# R7FA0L107 register map
Vendor: Renesas Electronics Corporation; Series: RA0; File version: 1.10.01
CPU: CM23 r1p0, little endian, no MPU, no FPU, VTOR, 2 interrupt priority bits, 64 interrupts
Registers are 16-bit, read-write, reset 0x0 unless marked. A register's access mark holds for its fields unless they carry their own. Offsets are from the block's base; [hi:lo] are bit positions; {n}, {i} and the like mark numbered series; 'fields as' and 'values as' point back to an identical list.

## IWDT — Independent Watchdog Timer
Base 0x40044400
0x00 IWDTRR 8-bit reset 0xFF — IWDT Refresh Register
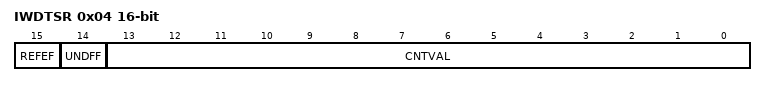
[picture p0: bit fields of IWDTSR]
0x04 IWDTSR — IWDT Status Register
  [15] REFEF — Refresh Error Flag
    0=No refresh error occurred; 1=Refresh error occurred
  [14] UNDFF — Underflow Flag
    0=No underflow occurred; 1=Underflow occurred
  [13:0] CNTVAL ro — Down-counter Value

## MSTP — Module Stop Control
Base 0x40047000
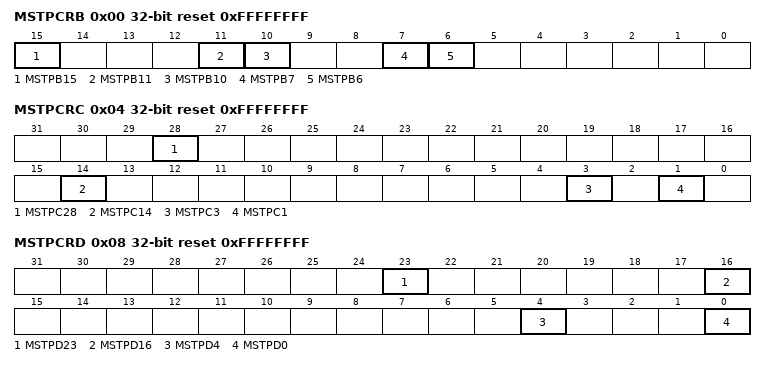
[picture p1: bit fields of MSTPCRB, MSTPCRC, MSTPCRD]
0x00 MSTPCRB 32-bit reset 0xFFFFFFFF — Module Stop Control Register B
  [all] fields
    0=Cancel the module-stop state; 1=Enter the module-stop state
  [15] MSTPB15 — Serial Interface UARTA Module Stop
  [11] MSTPB11 — I2C Bus Interface Module Stop
  [10] MSTPB10 — I2C Bus Interface Module Stop
  [7] MSTPB7 — Serial Array Unit 1 Module Stop
  [6] MSTPB6 — Serial Array Unit 0 Module Stop
0x04 MSTPCRC 32-bit reset 0xFFFFFFFF — Module Stop Control Register C
  [all] fields
    values as the fields of MSTPCRB
  [28] MSTPC28 — True Random Number Generator Module Stop
  [14] MSTPC14 — Event Link Controller Module Stop
  [3] MSTPC3 — Capacitive Touch Sensing Unit Module Stop
  [1] MSTPC1 — Cyclic Redundancy Check Calculator Module Stop
0x08 MSTPCRD 32-bit reset 0xFFFFFFFF — Module Stop Control Register D
  [all] fields
    values as the fields of MSTPCRB
  [23] MSTPD23 — Realtime Clock Module Stop
  [16] MSTPD16 — A/D Converter Module Stop
  [4] MSTPD4 — 32-bit Interval Timer Module Stop
  [0] MSTPD0 — Timer Array Unit 0 Module Stop

## CRC — CRC Calculator
Base 0x40074000
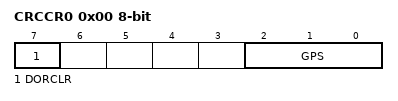
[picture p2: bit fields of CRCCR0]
0x00 CRCCR0 8-bit — CRC Control Register 0
  [7] DORCLR wo — CRCDOR/CRCDOR_HA Register Clear
    0=No effect; 1=Clear the CRCDOR/CRCDOR_HA register
  [2:0] GPS — CRC Generating Polynomial Switching
    3=16-bit CRC-CCITT (X16 + X12 + X5 + 1); 4=32-bit CRC-32 (X32 + X26 + X23 + X22 + X16 + X12 + X11 +X10 + X8 + X7 + X5 + X4 + X2 + X + 1); other=Others (No calculation is executed)
0x04 CRCDIR 32-bit — CRC Data Input Register
0x04 CRCDIR_BY 8-bit (alternate view of CRCDIR) — CRC Data Input Register
0x08 CRCDOR 32-bit — CRC Data Output Register
0x08 CRCDOR_HA (alternate view of CRCDOR) — CRC Data Output Register

## PORT0 — Port 0 Control
Base 0x400A0000
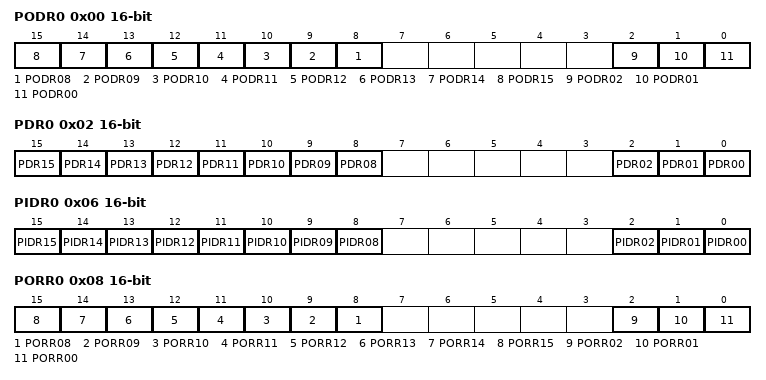
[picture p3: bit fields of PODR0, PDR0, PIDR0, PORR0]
0x00 PODR0 — Port 0 Output Data Register
  [all] fields
    0=Low output; 1=High output
  [n] PODR{n:02} (n=8..15) — P{n:03} Output Data
  [2] PODR02 — P002 Output Data
  [1] PODR01 — P001 Output Data
  [0] PODR00 — P000 Output Data
0x02 PDR0 — Port 0 Direction Register
  [all] fields
    0=Output 0; 1=Output 1
  [n] PDR{n:02} (n=8..15) — P{n:03} Direction
  [2] PDR02 — P002 Direction
  [1] PDR01 — P001 Direction
  [0] PDR00 — P000 Direction
0x06 PIDR0 ro (reset mask 0xF8) — Port 0 State Register
  [all] fields
    0=Low level; 1=High level
  [n] PIDR{n:02} (n=8..15) — P{n:03} State
  [2] PIDR02 — P002 State
  [1] PIDR01 — P001 State
  [0] PIDR00 — P000 State
0x08 PORR0 wo — Port 0 Output Reset Register
  [all] fields
    0=No effect on output; 1=Low output
  [n] PORR{n:02} (n=8..15) — P{n:03} Output Reset
  [2] PORR02 — P002 Output Reset
  [1] PORR01 — P001 Output Reset
  [0] PORR00 — P000 Output Reset
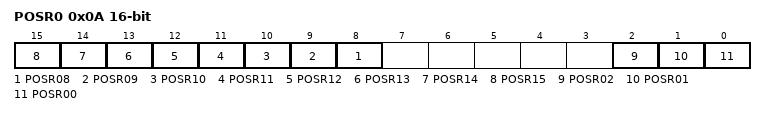
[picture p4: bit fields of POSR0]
0x0A POSR0 wo — Port 0 Output Set Register
  [all] fields
    0=No effect on output; 1=High output
  [n] POSR{n:02} (n=8..15) — P{n:03} Output Set
  [2] POSR02 — P002 Output Set
  [1] POSR01 — P001 Output Set
  [0] POSR00 — P000 Output Set

## PORT1 — Port 1 Control
Base 0x400A0020
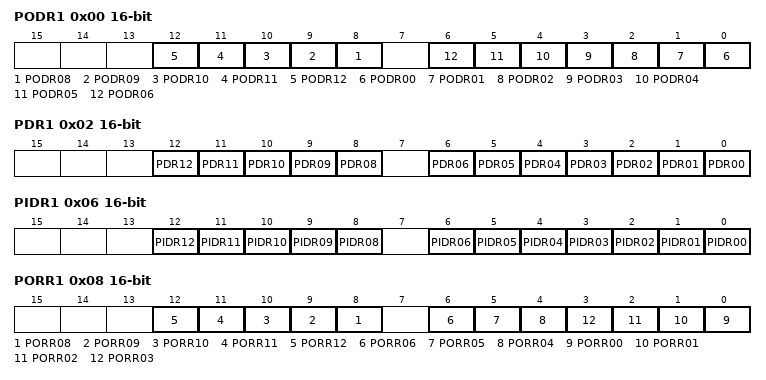
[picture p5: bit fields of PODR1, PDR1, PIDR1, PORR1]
0x00 PODR1 — Port 1 Output Data Register
  [all] fields
    0=Low output; 1=High output
  [n] PODR{n:02} (n=8..12) — P{n+100} Output Data
  [n] PODR{n:02} (n=0..6) — P{n+100} Output Data
0x02 PDR1 — Port 1 Direction Register
  [all] fields
    0=Output 0; 1=Output 1
  [n] PDR{n:02} (n=8..12) — P{n+100} Direction
  [n] PDR{n:02} (n=0..6) — P{n+100} Direction
0x06 PIDR1 ro (reset mask 0xE080) — Port 1 State Register
  [all] fields
    0=Low level; 1=High level
  [n] PIDR{n:02} (n=8..12) — P{n+100} State
  [n] PIDR{n:02} (n=0..6) — P{n+100} State
0x08 PORR1 wo — Port 1 Output Reset Register
  [all] fields
    0=No effect on output; 1=Low output
  [n] PORR{n:02} (n=8..12) — P{n+100} Output Reset
  [6] PORR06 — P106 Output Reset
  [5] PORR05 — P105 Output Reset
  [4] PORR04 — P103 Output Reset
  [n] PORR{n:02} (n=0..3) — P{n+100} Output Reset
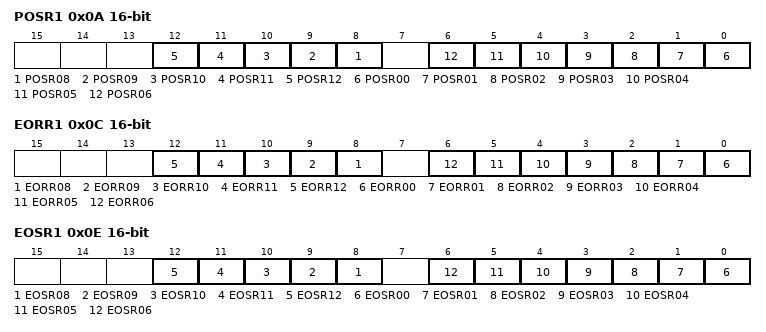
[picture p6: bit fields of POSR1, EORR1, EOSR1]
0x0A POSR1 wo — Port 1 Output Set Register
  [all] fields
    0=No effect on output; 1=High output
  [n] POSR{n:02} (n=8..12) — P{n+100} Output Set
  [n] POSR{n:02} (n=0..6) — P{n+100} Output Set
0x0C EORR1 — Port 1 Event Output Reset Register
  [all] fields
    0=No effect on output; 1=Low output
  [n] EORR{n:02} (n=8..12) — P{n+100} Event Output Reset
  [n] EORR{n:02} (n=0..6) — P{n+100} Event Output Reset
0x0E EOSR1 — Port 1 Event Output Set Register
  [all] fields
    0=No effect on output; 1=High output
  [n] EOSR{n:02} (n=8..12) — P{n+100} Event Output Set
  [n] EOSR{n:02} (n=0..6) — P{n+100} Event Output Set
